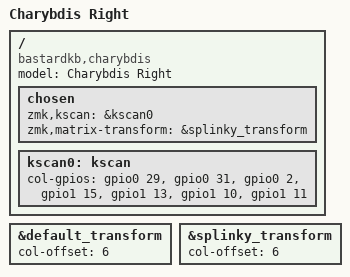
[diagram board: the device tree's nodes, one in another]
/*
 * Copyright (c) 2022 The ZMK Contributors
 *
 * SPDX-License-Identifier: MIT
 */

#include "charybdis.dtsi"

/ {
    model = "Charybdis Right";
    compatible = "bastardkb,charybdis";

    chosen {
        zmk,kscan = &kscan0;
        zmk,matrix-transform = &splinky_transform;
    };

    kscan0: kscan {
        col-gpios
            = <&gpio0 29 GPIO_ACTIVE_HIGH>
            , <&gpio0 31 GPIO_ACTIVE_HIGH>
            , <&gpio0 2  GPIO_ACTIVE_HIGH>
            , <&gpio1 15 GPIO_ACTIVE_HIGH>
            , <&gpio1 13 GPIO_ACTIVE_HIGH>
            , <&gpio1 10 GPIO_ACTIVE_HIGH>
            , <&gpio1 11 GPIO_ACTIVE_HIGH>
            ;
    };
};

&default_transform {
    col-offset = <6>;
};

&splinky_transform {
    col-offset = <6>;
};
